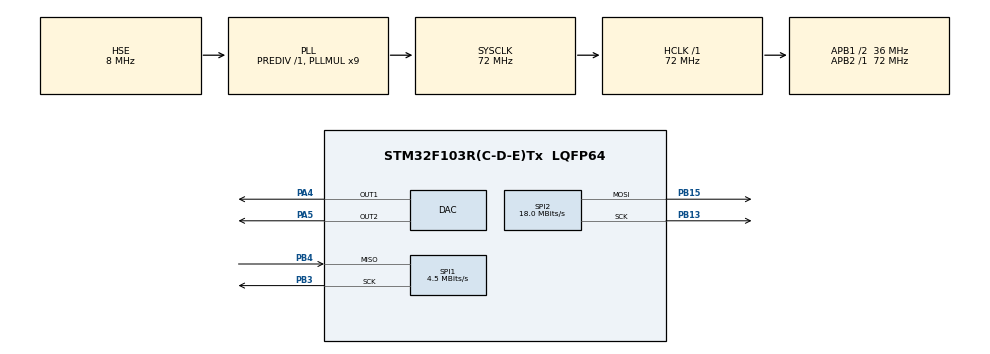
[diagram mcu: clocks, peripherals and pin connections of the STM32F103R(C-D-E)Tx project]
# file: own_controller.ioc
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DAC.DAC_Trigger=DAC_TRIGGER_SOFTWARE
DAC.DAC_Trigger2=DAC_TRIGGER_SOFTWARE
Dma.Request0=SPI1_RX
Dma.SPI1_RX.0.Direction=DMA_PERIPH_TO_MEMORY
Dma.SPI1_RX.0.Instance=DMA1_Channel2
Dma.SPI1_RX.0.MemDataAlignment=DMA_MDATAALIGN_BYTE
Dma.SPI1_RX.0.MemInc=DMA_MINC_ENABLE
Dma.SPI1_RX.0.Mode=DMA_NORMAL
Dma.SPI1_RX.0.PeriphDataAlignment=DMA_PDATAALIGN_BYTE
Dma.SPI1_RX.0.PeriphInc=DMA_PINC_DISABLE
Dma.SPI1_RX.0.Priority=DMA_PRIORITY_LOW
Mcu.Family=STM32F1
Mcu.Name=STM32F103R(C-D-E)Tx
Mcu.Package=LQFP64
NVIC.DMA1_Channel2_IRQn=true\:0\:0\:false\:false\:true\:false\:true\:true
NVIC.PriorityGroup=NVIC_PRIORITYGROUP_4
NVIC.SPI2_IRQn=true\:0\:0\:false\:false\:true\:true\:true\:true
PA13.Mode=Serial_Wire
PA13.Signal=SYS_JTMS-SWDIO
PA14.Mode=Serial_Wire
PA14.Signal=SYS_JTCK-SWCLK
PA4.Signal=COMP_DAC1_group
PA5.Signal=COMP_DAC2_group
PB13.Mode=TX_Only_Simplex_Unidirect_Master
PB13.Signal=SPI2_SCK
PB15.Mode=TX_Only_Simplex_Unidirect_Master
PB15.Signal=SPI2_MOSI
PB3.Mode=RX_Only_Simplex_Unidirect_Master
PB3.Signal=SPI1_SCK
PB4.Mode=RX_Only_Simplex_Unidirect_Master
PB4.Signal=SPI1_MISO
PD0-OSC_IN.Mode=HSE-External-Oscillator
PD0-OSC_IN.Signal=RCC_OSC_IN
PD1-OSC_OUT.Mode=HSE-External-Oscillator
PD1-OSC_OUT.Signal=RCC_OSC_OUT
ProjectManager.HeapSize=0x200
ProjectManager.StackSize=0x400
ProjectManager.TargetToolchain=MDK-ARM V5.32
RCC.AHBFreq_Value=72000000
RCC.APB1CLKDivider=RCC_HCLK_DIV2
RCC.APB1Freq_Value=36000000
RCC.APB1TimFreq_Value=72000000
RCC.APB2Freq_Value=72000000
RCC.APB2TimFreq_Value=72000000
RCC.HCLKFreq_Value=72000000
RCC.PLLMUL=RCC_PLL_MUL9
RCC.PLLSourceVirtual=RCC_PLLSOURCE_HSE
RCC.SYSCLKFreq_VALUE=72000000
RCC.SYSCLKSource=RCC_SYSCLKSOURCE_PLLCLK
RCC.USBFreq_Value=72000000
SH.COMP_DAC1_group.0=DAC_OUT1,DAC_OUT1
SH.COMP_DAC2_group.0=DAC_OUT2,DAC_OUT2
SPI1.BaudRatePrescaler=SPI_BAUDRATEPRESCALER_16
SPI1.CLKPhase=SPI_PHASE_1EDGE
SPI1.CLKPolarity=SPI_POLARITY_HIGH
SPI1.CRCCalculation=SPI_CRCCALCULATION_DISABLE
SPI1.CalculateBaudRate=4.5 MBits/s
SPI1.Direction=SPI_DIRECTION_2LINES_RXONLY
SPI1.Mode=SPI_MODE_MASTER
SPI1.VirtualType=VM_MASTER
SPI2.BaudRatePrescaler=SPI_BAUDRATEPRESCALER_2
SPI2.CalculateBaudRate=18.0 MBits/s
SPI2.Direction=SPI_DIRECTION_2LINES
SPI2.Mode=SPI_MODE_MASTER
SPI2.VirtualType=VM_MASTER
VP_IWDG_VS_IWDG.Mode=IWDG_Activate
board=custom

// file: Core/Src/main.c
/* USER CODE BEGIN Header */
/**
  ******************************************************************************
  * @file           : main.c
  * @brief          : Main program body
  ******************************************************************************
  * @attention
  *
  * Copyright (c) 2025 STMicroelectronics.
  * All rights reserved.
  *
  * This software is licensed under terms that can be found in the LICENSE file
  * in the root directory of this software component.
  * If no LICENSE file comes with this software, it is provided AS-IS.
  *
  ******************************************************************************
  */
/* USER CODE END Header */
#include "main.h"
#include "dac.h"
#include "dma.h"
#include "iwdg.h"
#include "spi.h"
#include "gpio.h"

/* USER CODE BEGIN Includes */
#include "encoder.h"

/* USER CODE END Includes */

/* USER CODE BEGIN PV */
extern uint8_T bissc_rx_buf[BISS_C_RX_BYTES];
uint32_T encoder_position = 0;
volatile uint8_t spiRxComplete = 0; // 用于标志SPI接收完成标志

/* USER CODE END PV */

void SystemClock_Config(void);

int main(void)
{

  /* MCU Configuration--------------------------------------------------------*/

  /* Reset of all peripherals, Initializes the Flash interface and the Systick. */
  HAL_Init();

  /* Configure the system clock */
  SystemClock_Config();

  /* Initialize all configured peripherals */
  MX_GPIO_Init();
  MX_DMA_Init();
  MX_DAC_Init();
  MX_IWDG_Init();
  MX_SPI1_Init();
  MX_SPI2_Init();
  /* USER CODE BEGIN 2 */
  HAL_SPI_Receive_DMA(&hspi1, (uint8_t *)bissc_rx_buf, BISS_C_RX_BYTES);	  //开启SPI1的DMA接收

  /* USER CODE END 2 */

  /* Infinite loop */
  /* USER CODE BEGIN WHILE */
  while (1)
  {
		HAL_IWDG_Refresh(&hiwdg);
    /* USER CODE END WHILE */

  }
}

void SystemClock_Config(void)
{
  RCC_OscInitTypeDef RCC_OscInitStruct = {0};
  RCC_ClkInitTypeDef RCC_ClkInitStruct = {0};

  /** Initializes the RCC Oscillators according to the specified parameters
  * in the RCC_OscInitTypeDef structure.
  */
  RCC_OscInitStruct.OscillatorType = RCC_OSCILLATORTYPE_LSI|RCC_OSCILLATORTYPE_HSE;
  RCC_OscInitStruct.HSEState = RCC_HSE_ON;
  RCC_OscInitStruct.HSEPredivValue = RCC_HSE_PREDIV_DIV1;
  RCC_OscInitStruct.HSIState = RCC_HSI_ON;
  RCC_OscInitStruct.LSIState = RCC_LSI_ON;
  RCC_OscInitStruct.PLL.PLLState = RCC_PLL_ON;
  RCC_OscInitStruct.PLL.PLLSource = RCC_PLLSOURCE_HSE;
  RCC_OscInitStruct.PLL.PLLMUL = RCC_PLL_MUL9;
  if (HAL_RCC_OscConfig(&RCC_OscInitStruct) != HAL_OK)
  {
    Error_Handler();
  }

  /** Initializes the CPU, AHB and APB buses clocks
  */
  RCC_ClkInitStruct.ClockType = RCC_CLOCKTYPE_HCLK|RCC_CLOCKTYPE_SYSCLK
                              |RCC_CLOCKTYPE_PCLK1|RCC_CLOCKTYPE_PCLK2;
  RCC_ClkInitStruct.SYSCLKSource = RCC_SYSCLKSOURCE_PLLCLK;
  RCC_ClkInitStruct.AHBCLKDivider = RCC_SYSCLK_DIV1;
  RCC_ClkInitStruct.APB1CLKDivider = RCC_HCLK_DIV2;
  RCC_ClkInitStruct.APB2CLKDivider = RCC_HCLK_DIV1;

  if (HAL_RCC_ClockConfig(&RCC_ClkInitStruct, FLASH_LATENCY_2) != HAL_OK)
  {
    Error_Handler();
  }
}

void Error_Handler(void)
{
  __disable_irq();
  while (1)
  {
  }
}
